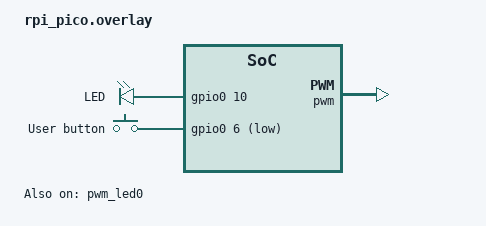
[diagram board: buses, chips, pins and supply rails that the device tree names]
#include "rpi_pico-pinctrl.dtsi"

/ {
pwm_leds {
		compatible = "pwm-leds";
		status = "disabled";
		pwm_led1: pwm_led_1 {
			pwms = <&pwm 7 PWM_MSEC(20) PWM_POLARITY_NORMAL>;
			label = "PWM_LED";
		};
	};

	leds {
		compatible = "gpio-leds";
		led2: led_2 {
			gpios = <&gpio0 10 GPIO_ACTIVE_HIGH>;
			label = "LED";
		};
	};

	 buttons {
             compatible = "gpio-keys";
             button0: button_0 {
                     gpios = < &gpio0 6 (GPIO_PULL_UP | GPIO_ACTIVE_LOW)>;
                     label = "User button";
             };
             /* ... other buttons ... */
     };

	aliases {
		pwm-led1 = &pwm_led1;
		sw0 = &button0;
		led2 = &led2;
	};
};


&pwm_led0 {
	status = "okay";
};

&pwm {
	status = "okay";

	pinctrl-0 = <&pwm_chn_used>;

	// for pwm chanel 3 A and B

	divider-frac-3 = <15>;
	divider-int-3 = <255>;
	
	// for pwm chanel 4 A and B
	
	divider-frac-4 = <15>;
	divider-int-4 = <255>;
};
